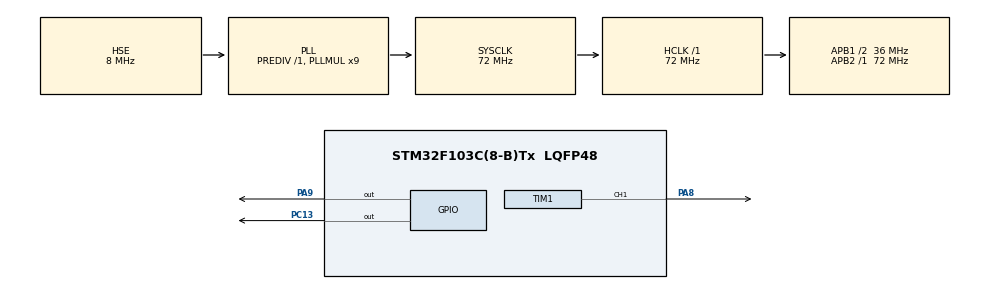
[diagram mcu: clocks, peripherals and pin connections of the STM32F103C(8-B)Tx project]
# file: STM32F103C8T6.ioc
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Mcu.Family=STM32F1
Mcu.Name=STM32F103C(8-B)Tx
Mcu.Package=LQFP48
NVIC.PriorityGroup=NVIC_PRIORITYGROUP_4
PA13.Mode=Serial_Wire
PA13.Signal=SYS_JTMS-SWDIO
PA14.Mode=Serial_Wire
PA14.Signal=SYS_JTCK-SWCLK
PA8.GPIO_Speed=GPIO_SPEED_FREQ_HIGH
PA8.Signal=S_TIM1_CH1
PA9.Signal=GPIO_Output
PC13-TAMPER-RTC.Signal=GPIO_Output
PC14-OSC32_IN.Mode=LSE-External-Oscillator
PC14-OSC32_IN.Signal=RCC_OSC32_IN
PC15-OSC32_OUT.Mode=LSE-External-Oscillator
PC15-OSC32_OUT.Signal=RCC_OSC32_OUT
PD0-OSC_IN.Mode=HSE-External-Oscillator
PD0-OSC_IN.Signal=RCC_OSC_IN
PD1-OSC_OUT.Mode=HSE-External-Oscillator
PD1-OSC_OUT.Signal=RCC_OSC_OUT
ProjectManager.HeapSize=0x200
ProjectManager.StackSize=0x400
ProjectManager.TargetToolchain=MDK-ARM V5
RCC.AHBFreq_Value=72000000
RCC.APB1CLKDivider=RCC_HCLK_DIV2
RCC.APB1Freq_Value=36000000
RCC.APB1TimFreq_Value=72000000
RCC.APB2Freq_Value=72000000
RCC.APB2TimFreq_Value=72000000
RCC.HCLKFreq_Value=72000000
RCC.PLLMUL=RCC_PLL_MUL9
RCC.PLLSourceVirtual=RCC_PLLSOURCE_HSE
RCC.SYSCLKFreq_VALUE=72000000
RCC.SYSCLKSource=RCC_SYSCLKSOURCE_PLLCLK
RCC.USBFreq_Value=72000000
SH.S_TIM1_CH1.0=TIM1_CH1,PWM Generation1 CH1
TIM1.AutoReloadPreload=TIM_AUTORELOAD_PRELOAD_ENABLE
TIM1.Channel-PWM\ Generation1\ CH1=TIM_CHANNEL_1
TIM1.OCMode_PWM-PWM\ Generation1\ CH1=TIM_OCMODE_PWM1
TIM1.Period=19999
TIM1.Prescaler=71
TIM1.Pulse-PWM\ Generation1\ CH1=1499
VP_TIM1_VS_ClockSourceINT.Mode=Internal
board=custom

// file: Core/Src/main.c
/* USER CODE BEGIN Header */
/**
  ******************************************************************************
  * @file           : main.c
  * @brief          : Main program body
  ******************************************************************************
  * @attention
  *
  * <h2><center>&copy; Copyright (c) 2023 STMicroelectronics.
  * All rights reserved.</center></h2>
  *
  * This software component is licensed by ST under BSD 3-Clause license,
  * the "License"; You may not use this file except in compliance with the
  * License. You may obtain a copy of the License at:
  *                        opensource.org/licenses/BSD-3-Clause
  *
  ******************************************************************************
  */
/* USER CODE END Header */
#include "main.h"

/* USER CODE BEGIN Includes */
#include "player.h"
/* USER CODE END Includes */

TIM_HandleTypeDef htim1;

void SystemClock_Config(void);
static void MX_GPIO_Init(void);
static void MX_TIM1_Init(void);

int main(void)
{

  /* MCU Configuration--------------------------------------------------------*/

  /* Reset of all peripherals, Initializes the Flash interface and the Systick. */
  HAL_Init();

  /* Configure the system clock */
  SystemClock_Config();

  /* Initialize all configured peripherals */
  MX_GPIO_Init();
  MX_TIM1_Init();
  /* USER CODE BEGIN 2 */
  HAL_TIM_PWM_Start(&htim1,TIM_CHANNEL_1);
  HAL_TIM_PWM_Start(&htim1,TIM_CHANNEL_2);
  int Points[17]={0,35,70,110,130,175,210,245,290,330,365,395,435,475,510,545,585};
  //              0, 1, 2, 3 , 4 , 5 , 6 , 7 , 8 , 9 , 10, 11, 12, 13, 14, 15, 16
  int StartPoint=1060;
  htim1.Instance->CCR1=StartPoint+Points[P2__];
  HAL_Delay(2000);
/*   htim1.Instance->CCR1=StartPoint+Points[P3_];
  HAL_Delay(2000); */
  /* USER CODE END 2 */

  /* Infinite loop */
  while (1)
  {

    /* USER CODE BEGIN 3 */
    Note CangHaiYiShengXiao[49]={{P6_,I8_},{P5_,I16},{P3_,I8},{P2_,I8},{P1_,I2},{P3_,I8_},{P2_,I16},{P1_,I8},{P6,I8},{P5,I2},\
    {P5,I8_},{P6,I16},{P5,I8},{P6,I8},{P1_,I8_},{P2_,I16},{P3_,I8},{P5_,I8},{P6_,I8_},{P5_,I16},{P3_,I16},{P2_,I16},{P1_,I8},{P2_,I2},\
    {P6_,I8},{P6_,I16},{P5_,I16},{P3_,I8},{P2_,I8},{P1_,I2},{P3_,I8_},{P2_,I16},{P1_,I8},{P6,I8},{P5,I2},
    {P5,I8_},{P6,I16},{P5,I8},{P6,I8},{P1_,I8_},{P2_,I16},{P3_,I8},{P5_,I8},{P6_,I8_},{P5_,I16},{P3_,I16},{P2_,I16},{P1_,I8},{P2_,I2}};//沧海一声笑

    Note NvErQing[90]={{P5,I8},{P6,I8},{P1_,I4_},{P2_,I8},{P3_,I8},{P7,I8},{P6,I16},{P7,I16},{P5,I8},{P6,I2},//鸳鸯双皙蝶双飞
    {P1_,I8},{P2_,I8},{P3_,I4},{P5_,I8},{P6_,I8},{P1_,I8},{P2_,I16},{P3_,I16},{P4_,I8},{P3_,I2},//满园春色惹人醉
    {P3_,I8},{P5_,I8},{P6_,I4_},{P5_,I8},{P6_,I4},{P6,I8},{P3_,I8},{P2_,I4_},{P1_,I8},{P2_,I4},//悄悄问圣僧女儿美不美
    {P3_,I4},{P5,I4_},{P6,I8},{P7,I8},{P3_,I4},{P6,I8},{P1_,I2},//女儿美不美
    {P5_,I8},{P5_,I8},{P6_,I8},{P1__,I8},{P7_,I4},{P6_,I16},{P5_,I16},{P6_,I2},//说什么王权富贵
    {P5_,I8},{P5_,I8},{P6_,I8},{P1__,I8},{P7_,I4},{P6_,I16},{P5_,I16},{P3_,I2},///怕什么戒律清规
    {P5,I8},{P6,I8},{P1_,I4_},{P2_,I8},{P3_,I8},{P7,I8},{P6,I16},{P7,I16},{P5,I8},{P6,I2},//只愿天长地久
    {P1_,I8},{P2_,I8},{P3_,I4},{P5_,I8},{P6_,I8},{P1_,I8},{P2_,I16},{P3_,I16},{P4_,I8},{P3_,I2},//与我意中人儿紧相随
    {P3_,I8},{P5_,I8},{P6_,I4_},{P5_,I8},{P6_,I4},{P6,I8},{P3_,I8},{P2_,I4_},{P1_,I8},{P2_,I4},//爱恋伊爱恋伊
    {P3_,I4},{P5,I4_},{P6,I8},{P7,I8},{P3_,I4},{P6,I8},{P1_,I2},//愿今生常相随
    };

    //Note ForAlice[9]={{P3__,I16},{P1__,I16},{P3__,I16},{P1__,I16},{P3__,I16},{P7_,I16},{P2__,I16},{P1__,I16},{P6_,I16}};
    Note Yinjie[17]={{P1,I4},{P2,I4},{P3,I4},{P4,I4},{P5,I4},{P6,I4},{P7,I4},{P1_,I4},{P2_,I4},{P3_,I4},{P4_,I4},{P5_,I4},{P6_,I4},{P7_,I4},{P1__,I4},{P2__,I4},{P3__,I4}};//音阶
    double scal=0.8;
    int lastInterval=1000;
    int NotesLength=sizeof(NvErQing)/sizeof(Note);
    Note * Playing=NvErQing;
  for(int i=0;i<NotesLength;i++)
    {
      htim1.Instance->CCR1=StartPoint+Points[Playing[i].pitchMap];
      HAL_GPIO_TogglePin(GPIOC,GPIO_PIN_13);
      HAL_Delay(lastInterval-20);
      HAL_GPIO_WritePin(GPIOA,GPIO_PIN_9,GPIO_PIN_SET);
      HAL_Delay(18);
      HAL_GPIO_WritePin(GPIOA,GPIO_PIN_9,GPIO_PIN_RESET);
      HAL_Delay(20);
      lastInterval=Playing[i].interval*scal;
    }

  }
  /* USER CODE END 3 */
}

void SystemClock_Config(void)
{
  RCC_OscInitTypeDef RCC_OscInitStruct = {0};
  RCC_ClkInitTypeDef RCC_ClkInitStruct = {0};

  /** Initializes the RCC Oscillators according to the specified parameters
  * in the RCC_OscInitTypeDef structure.
  */
  RCC_OscInitStruct.OscillatorType = RCC_OSCILLATORTYPE_HSE;
  RCC_OscInitStruct.HSEState = RCC_HSE_ON;
  RCC_OscInitStruct.HSEPredivValue = RCC_HSE_PREDIV_DIV1;
  RCC_OscInitStruct.HSIState = RCC_HSI_ON;
  RCC_OscInitStruct.PLL.PLLState = RCC_PLL_ON;
  RCC_OscInitStruct.PLL.PLLSource = RCC_PLLSOURCE_HSE;
  RCC_OscInitStruct.PLL.PLLMUL = RCC_PLL_MUL9;
  if (HAL_RCC_OscConfig(&RCC_OscInitStruct) != HAL_OK)
  {
    Error_Handler();
  }
  /** Initializes the CPU, AHB and APB buses clocks
  */
  RCC_ClkInitStruct.ClockType = RCC_CLOCKTYPE_HCLK|RCC_CLOCKTYPE_SYSCLK
                              |RCC_CLOCKTYPE_PCLK1|RCC_CLOCKTYPE_PCLK2;
  RCC_ClkInitStruct.SYSCLKSource = RCC_SYSCLKSOURCE_PLLCLK;
  RCC_ClkInitStruct.AHBCLKDivider = RCC_SYSCLK_DIV1;
  RCC_ClkInitStruct.APB1CLKDivider = RCC_HCLK_DIV2;
  RCC_ClkInitStruct.APB2CLKDivider = RCC_HCLK_DIV1;

  if (HAL_RCC_ClockConfig(&RCC_ClkInitStruct, FLASH_LATENCY_2) != HAL_OK)
  {
    Error_Handler();
  }
}

static void MX_TIM1_Init(void)
{

  TIM_ClockConfigTypeDef sClockSourceConfig = {0};
  TIM_MasterConfigTypeDef sMasterConfig = {0};
  TIM_OC_InitTypeDef sConfigOC = {0};
  TIM_BreakDeadTimeConfigTypeDef sBreakDeadTimeConfig = {0};

  htim1.Instance = TIM1;
  htim1.Init.Prescaler = 71;
  htim1.Init.CounterMode = TIM_COUNTERMODE_UP;
  htim1.Init.Period = 19999;
  htim1.Init.ClockDivision = TIM_CLOCKDIVISION_DIV1;
  htim1.Init.RepetitionCounter = 0;
  htim1.Init.AutoReloadPreload = TIM_AUTORELOAD_PRELOAD_ENABLE;
  if (HAL_TIM_Base_Init(&htim1) != HAL_OK)
  {
    Error_Handler();
  }
  sClockSourceConfig.ClockSource = TIM_CLOCKSOURCE_INTERNAL;
  if (HAL_TIM_ConfigClockSource(&htim1, &sClockSourceConfig) != HAL_OK)
  {
    Error_Handler();
  }
  if (HAL_TIM_PWM_Init(&htim1) != HAL_OK)
  {
    Error_Handler();
  }
  sMasterConfig.MasterOutputTrigger = TIM_TRGO_RESET;
  sMasterConfig.MasterSlaveMode = TIM_MASTERSLAVEMODE_DISABLE;
  if (HAL_TIMEx_MasterConfigSynchronization(&htim1, &sMasterConfig) != HAL_OK)
  {
    Error_Handler();
  }
  sConfigOC.OCMode = TIM_OCMODE_PWM1;
  sConfigOC.Pulse = 1499;
  sConfigOC.OCPolarity = TIM_OCPOLARITY_HIGH;
  sConfigOC.OCNPolarity = TIM_OCNPOLARITY_HIGH;
  sConfigOC.OCFastMode = TIM_OCFAST_DISABLE;
  sConfigOC.OCIdleState = TIM_OCIDLESTATE_RESET;
  sConfigOC.OCNIdleState = TIM_OCNIDLESTATE_RESET;
  if (HAL_TIM_PWM_ConfigChannel(&htim1, &sConfigOC, TIM_CHANNEL_1) != HAL_OK)
  {
    Error_Handler();
  }
  sBreakDeadTimeConfig.OffStateRunMode = TIM_OSSR_DISABLE;
  sBreakDeadTimeConfig.OffStateIDLEMode = TIM_OSSI_DISABLE;
  sBreakDeadTimeConfig.LockLevel = TIM_LOCKLEVEL_OFF;
  sBreakDeadTimeConfig.DeadTime = 0;
  sBreakDeadTimeConfig.BreakState = TIM_BREAK_DISABLE;
  sBreakDeadTimeConfig.BreakPolarity = TIM_BREAKPOLARITY_HIGH;
  sBreakDeadTimeConfig.AutomaticOutput = TIM_AUTOMATICOUTPUT_DISABLE;
  if (HAL_TIMEx_ConfigBreakDeadTime(&htim1, &sBreakDeadTimeConfig) != HAL_OK)
  {
    Error_Handler();
  }
  HAL_TIM_MspPostInit(&htim1);

}

static void MX_GPIO_Init(void)
{
  GPIO_InitTypeDef GPIO_InitStruct = {0};

  /* GPIO Ports Clock Enable */
  __HAL_RCC_GPIOC_CLK_ENABLE();
  __HAL_RCC_GPIOD_CLK_ENABLE();
  __HAL_RCC_GPIOA_CLK_ENABLE();

  /*Configure GPIO pin Output Level */
  HAL_GPIO_WritePin(GPIOC, GPIO_PIN_13, GPIO_PIN_RESET);

  /*Configure GPIO pin Output Level */
  HAL_GPIO_WritePin(GPIOA, GPIO_PIN_9, GPIO_PIN_RESET);

  /*Configure GPIO pin : PC13 */
  GPIO_InitStruct.Pin = GPIO_PIN_13;
  GPIO_InitStruct.Mode = GPIO_MODE_OUTPUT_PP;
  GPIO_InitStruct.Pull = GPIO_NOPULL;
  GPIO_InitStruct.Speed = GPIO_SPEED_FREQ_LOW;
  HAL_GPIO_Init(GPIOC, &GPIO_InitStruct);

  /*Configure GPIO pin : PA9 */
  GPIO_InitStruct.Pin = GPIO_PIN_9;
  GPIO_InitStruct.Mode = GPIO_MODE_OUTPUT_PP;
  GPIO_InitStruct.Pull = GPIO_NOPULL;
  GPIO_InitStruct.Speed = GPIO_SPEED_FREQ_LOW;
  HAL_GPIO_Init(GPIOA, &GPIO_InitStruct);

}

void Error_Handler(void)
{
  __disable_irq();
  while (1)
  {
  }
}

/************************ (C) COPYRIGHT STMicroelectronics *****END OF FILE****/
